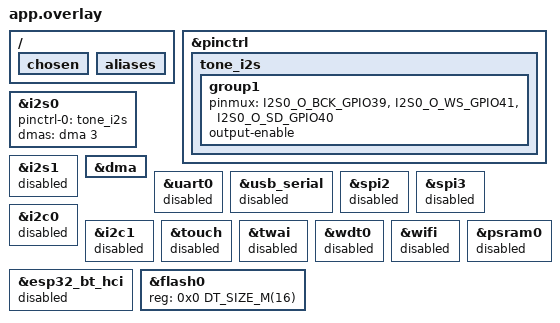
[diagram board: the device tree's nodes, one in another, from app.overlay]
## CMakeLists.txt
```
cmake_minimum_required(VERSION 3.20.0)
find_package(Zephyr REQUIRED HINTS $ENV{ZEPHYR_BASE})
project(independent_tone C)
target_sources(app PRIVATE src/main.c src/sequence.c)
```

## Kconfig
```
mainmenu "Independent Zephyr tone test"

config TONE_LEFT
    bool "Drive left slot instead of right (other slot is zero)"
    default n

source "Kconfig.zephyr"
```

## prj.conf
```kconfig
CONFIG_BOOTLOADER_MCUBOOT=n
CONFIG_ESP_SIMPLE_BOOT=y
CONFIG_I2S=y
CONFIG_I2S_ESP32_TX_BLOCK_COUNT=8
CONFIG_I2S_ESP32_RX_BLOCK_COUNT=1
CONFIG_MAIN_STACK_SIZE=3072
CONFIG_HEAP_MEM_POOL_SIZE=4096
CONFIG_SIZE_OPTIMIZATIONS=y
CONFIG_SERIAL=n
CONFIG_CONSOLE=n
CONFIG_UART_CONSOLE=n
CONFIG_PRINTK=n
CONFIG_BOOT_BANNER=n
CONFIG_LOG=n
CONFIG_GPIO=y
CONFIG_WIFI=n
CONFIG_BT=n
CONFIG_NETWORKING=n
CONFIG_FLASH=n
CONFIG_NVS=n
CONFIG_FILE_SYSTEM=n
CONFIG_SETTINGS=n
CONFIG_ESP_SPIRAM=n
CONFIG_WATCHDOG=n
CONFIG_PM=n
CONFIG_TIMESLICING=n
```

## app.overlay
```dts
#include <zephyr/dt-bindings/pinctrl/esp32s3-pinctrl.h>

/ {
    chosen {
        /delete-property/ zephyr,console;
        /delete-property/ zephyr,shell-uart;
        /delete-property/ zephyr,bt-hci;
    };
    aliases {
        /delete-property/ sw0;
        /delete-property/ uart-0;
        /delete-property/ i2c-0;
        /delete-property/ watchdog0;
    };
    /delete-node/ buttons;
};

&pinctrl {
    tone_i2s: tone_i2s {
        group1 {
            pinmux = <I2S0_O_BCK_GPIO39>, <I2S0_O_WS_GPIO41>, <I2S0_O_SD_GPIO40>;
            output-enable;
        };
    };
};

&i2s0 {
    status = "okay";
    pinctrl-0 = <&tone_i2s>;
    pinctrl-names = "default";
    /* TX only. No input, no MCLK pin and no amplifier SD pin. */
    dmas = <&dma 3>; /* ESP32 GDMA pair 1, TX (odd channel ID) */
    dma-names = "tx";
};
&i2s1 { status = "disabled"; };
&dma { status = "okay"; };
&uart0 { status = "disabled"; };
&usb_serial { status = "disabled"; };
&spi2 { status = "disabled"; };
&spi3 { status = "disabled"; };
&i2c0 { status = "disabled"; };
&i2c1 { status = "disabled"; };
&touch { status = "disabled"; };
&twai { status = "disabled"; };
&wdt0 { status = "disabled"; };
&wifi { status = "disabled"; };
&esp32_bt_hci { status = "disabled"; };
&psram0 { status = "disabled"; };
&flash0 { reg = <0x0 DT_SIZE_M(16)>; };
```

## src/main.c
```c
#include <zephyr/device.h>
#include <zephyr/drivers/i2s.h>
#include <zephyr/kernel.h>
#include <zephyr/sys/util.h>
#include "sequence.h"

#define BLOCK_BYTES (TONE_BLOCK_FRAMES * 2u * sizeof(int16_t))
#define PREFILL 6u
K_MEM_SLAB_DEFINE_STATIC(tx_slab, BLOCK_BYTES, 10, 4);
BUILD_ASSERT(BLOCK_BYTES <= 4092);
BUILD_ASSERT(sizeof(int16_t) == 2);

/* RAM only, inspectable with a debugger. No playback-time output or retries.
 * A failed run must not restart tones or silently conceal a DMA/queue error. */
volatile int tone_fault;
volatile uint32_t tone_accepted_blocks;

int main(void)
{
    const struct device *i2s = DEVICE_DT_GET(DT_NODELABEL(i2s0));
    struct i2s_config cfg = {
        .word_size = 16,
        .channels = 2,
        .format = I2S_FMT_DATA_FORMAT_I2S | I2S_FMT_DATA_ORDER_MSB,
        .options = I2S_OPT_FRAME_CLK_MASTER | I2S_OPT_BIT_CLK_MASTER,
        .frame_clk_freq = TONE_RATE,
        .mem_slab = &tx_slab,
        .block_size = BLOCK_BYTES,
        .timeout = 500,
    };
    int error = -ENODEV;
    uint32_t frame = 0;
    bool running = false;
    bool configured = false;

    if (!device_is_ready(i2s)) {
        goto failed;
    }
    error = i2s_configure(i2s, I2S_DIR_TX, &cfg);
    if (error) {
        goto failed;
    }
    configured = true;
    for (;;) {
        void *block;
        error = k_mem_slab_alloc(&tx_slab, &block, K_MSEC(500));
        if (error) {
            goto failed;
        }
        tone_fill(frame, block, TONE_BLOCK_FRAMES, IS_ENABLED(CONFIG_TONE_LEFT));
        error = i2s_write(i2s, block, BLOCK_BYTES);
        if (error) {
            k_mem_slab_free(&tx_slab, block); /* ownership only transfers on success */
            goto failed;
        }
        ++tone_accepted_blocks;
        /* Saturate after finite sequence; keep buffered zero PCM and clocks forever. */
        if (frame < TONE_REFERENCE_SECONDS * TONE_RATE) {
            frame += TONE_BLOCK_FRAMES;
        }
        if (!running && tone_accepted_blocks == PREFILL) {
            error = i2s_trigger(i2s, I2S_DIR_TX, I2S_TRIGGER_START);
            if (error) {
                goto failed;
            }
            running = true;
        }
    }
failed:
    tone_fault = error;
    if (configured) {
        (void)i2s_trigger(i2s, I2S_DIR_TX, I2S_TRIGGER_DROP);
    }
    k_sleep(K_FOREVER);
    return 0;
}
```

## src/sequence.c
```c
#include "sequence.h"
#include "pcm_tables.h"

void tone_fill(uint32_t first_frame, int16_t *stereo, size_t frames, int left)
{
    const unsigned slot = left ? 0u : 1u;
    for (size_t i = 0; i < frames; ++i) {
        uint32_t frame = first_frame + (uint32_t)i;
        int16_t sample = 0;
        if (frame >= TONE_INITIAL_SECONDS * TONE_RATE &&
            frame < TONE_END_SECONDS * TONE_RATE) {
            frame -= TONE_INITIAL_SECONDS * TONE_RATE;
            const unsigned stage = frame / ((TONE_SECONDS + TONE_GAP_SECONDS) * TONE_RATE);
            const unsigned offset = frame % ((TONE_SECONDS + TONE_GAP_SECONDS) * TONE_RATE);
            if (stage < 6u && offset < TONE_SECONDS * TONE_RATE) {
                const struct tone_pcm *p = &tone_pcm[stage];
                if (offset < PCM_FADE_FRAMES) {
                    sample = p->fade_in[offset];
                } else if (offset >= TONE_SECONDS * TONE_RATE - PCM_FADE_FRAMES) {
                    sample = p->fade_out[offset - (TONE_SECONDS * TONE_RATE - PCM_FADE_FRAMES)];
                } else {
                    sample = p->period[offset % PCM_PERIOD_FRAMES];
                }
            }
        }
        stereo[2u * i] = 0;
        stereo[2u * i + 1u] = 0;
        stereo[2u * i + slot] = sample;
    }
}
```

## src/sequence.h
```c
#ifndef TONE_SEQUENCE_H
#define TONE_SEQUENCE_H
#include <stddef.h>
#include <stdint.h>
#define TONE_RATE 44100u
#define TONE_BLOCK_FRAMES 882u /* 20 ms, below ESP32 driver's 4092-byte limit */
#define TONE_SECONDS 5u
#define TONE_GAP_SECONDS 2u
#define TONE_INITIAL_SECONDS 5u
#define TONE_END_SECONDS 45u /* end of final fade; zeros continue indefinitely */
#define TONE_REFERENCE_SECONDS 47u /* include two seconds of final silence */
/* Stateless absolute frame indexing; no phase reset at DMA buffer boundaries. */
void tone_fill(uint32_t first_frame, int16_t *stereo, size_t frames, int left);
#endif
```
